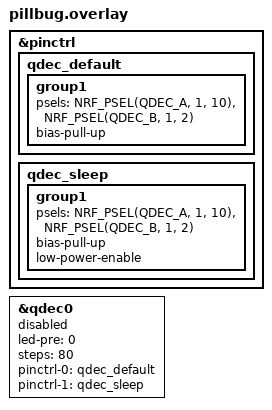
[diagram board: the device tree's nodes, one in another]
/*
 * Copyright (c) 2023 The ZMK Contributors
 *
 * SPDX-License-Identifier: MIT
 */

/ {
    /delete-node/ encoder;
};

&pinctrl {
    qdec_default: qdec_default {
        group1 {
            psels = <NRF_PSEL(QDEC_A, 1, 10)>,
                    <NRF_PSEL(QDEC_B, 1, 2)>;
            bias-pull-up;
        };
    };

// need second set of pins defined if deep sleep is enabled
    qdec_sleep: qdec_sleep {
        group1 {
            psels = <NRF_PSEL(QDEC_A, 1, 10)>,
                    <NRF_PSEL(QDEC_B, 1, 2)>;
            bias-pull-up; // TODO: find out if this makes sense with low-power-enable
            low-power-enable;
        };
    };
};

// Set up the QDEC hardware based driver and give it the same label as the deleted node.
encoder: &qdec0 {
    status = "disabled";
    led-pre = <0>;
    steps = <80>;
    pinctrl-0 = <&qdec_default>;
    pinctrl-1 = <&qdec_sleep>;
    pinctrl-names = "default", "sleep";
};
